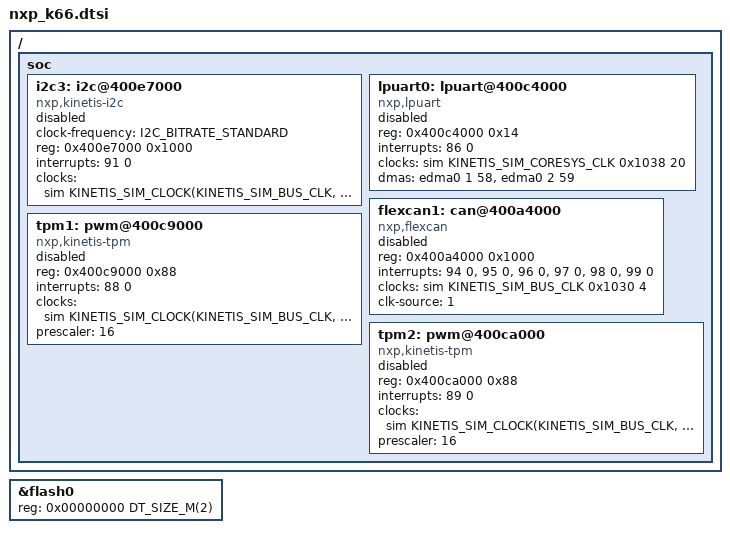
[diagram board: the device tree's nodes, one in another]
/*
 * Copyright (c) 2020 DENX Software Engineering GmbH
 *
 * SPDX-License-Identifier: Apache-2.0
 */

#include <mem.h>
#include <freq.h>
#include <nxp/nxp_k6x.dtsi>

&flash0 {
	reg = <0x00000000 DT_SIZE_M(2)>;
};

/ {
	soc {
		i2c3: i2c@400e7000 {
			compatible = "nxp,kinetis-i2c";
			clock-frequency = <I2C_BITRATE_STANDARD>;
			#address-cells = <1>;
			#size-cells = <0>;
			reg = <0x400e7000 0x1000>;
			interrupts = <91 0>;
			clocks = <&sim KINETIS_SIM_CLOCK(KINETIS_SIM_BUS_CLK, 0x1028, 7)>;
			status = "disabled";
		};

		lpuart0: lpuart@400c4000 {
			compatible = "nxp,lpuart";
			reg = <0x400c4000 0x14>;
			interrupts = <86 0>;
			clocks = <&sim KINETIS_SIM_CORESYS_CLK 0x1038 20>;
			dmas = <&edma0 1 58>, <&edma0 2 59>;
			dma-names = "rx", "tx";
			status = "disabled";
		};

		flexcan1: can@400a4000 {
			compatible = "nxp,flexcan";
			reg = <0x400a4000 0x1000>;
			interrupts = <94 0>, <95 0>, <96 0>, <97 0>, <98 0>, <99 0>;
			interrupt-names = "mb-0-15", "bus-off", "error", "tx-warning",
					  "rx-warning", "wake-up";
			clocks = <&sim KINETIS_SIM_BUS_CLK 0x1030 4>;
			clk-source = <1>;
			status = "disabled";
		};

		tpm1: pwm@400c9000 {
			compatible = "nxp,kinetis-tpm";
			reg = <0x400c9000 0x88>;
			interrupts = <88 0>;
			clocks = <&sim KINETIS_SIM_CLOCK(KINETIS_SIM_BUS_CLK, 0x103c, 25)>;
			prescaler = <16>;
			status = "disabled";
			#pwm-cells = <3>;
		};

		tpm2: pwm@400ca000 {
			compatible = "nxp,kinetis-tpm";
			reg = <0x400ca000 0x88>;
			interrupts = <89 0>;
			clocks = <&sim KINETIS_SIM_CLOCK(KINETIS_SIM_BUS_CLK, 0x103c, 26)>;
			prescaler = <16>;
			status = "disabled";
			#pwm-cells = <3>;
		};
	};
};
